# PTM280xx register map
File version: 0.4
Registers are 32-bit, read-write, reset 0x0 unless marked. A register's access mark holds for its fields unless they carry their own. Offsets are from the block's base; [hi:lo] are bit positions; {n}, {i} and the like mark numbered series.

## UART0 — Universal Asynchronous Receiver Transmitter
Base 0x40004400
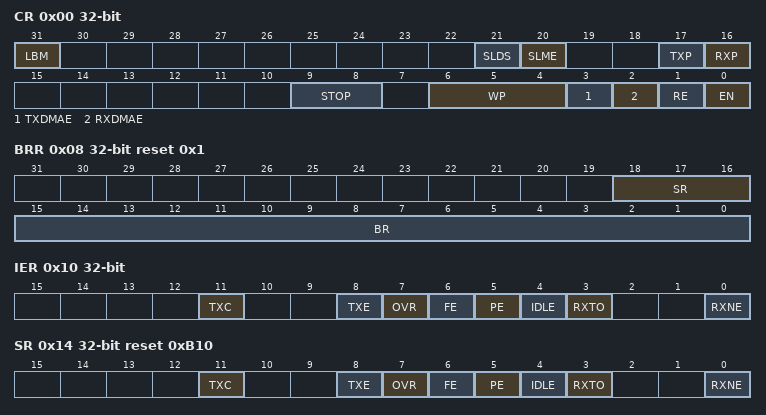
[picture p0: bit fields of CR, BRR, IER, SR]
0x00 CR — Control Register
  [31] LBM — loopback mode
  [21] SLDS — Single-line direction setting
  [20] SLME — Single-line mode enable
  [17] TXP — Transmitter polarity control
  [16] RXP — Receiver polarity control
  [9:8] STOP — Stop bit length
  [6:4] WP — Word length and parity config
  [3] TXDMAE — Tx DMA request enable
  [2] RXDMAE — Rx DMA request enable
  [1] RE — Receive enable
  [0] EN — UART enable
0x08 BRR reset 0x1 — Baud Rate Register
  [18:16] SR — Sample rate
  [15:0] BR — Baud rate control
0x10 IER — Interrupt Enable Register
  [11] TXC — Transmit complete interrupt enable
  [8] TXE — Transmit FIFO empty interrupt enable
  [7] OVR — Receive/Receive-FIFO overflow interrupt enable
  [6] FE — frame error interrupt enable
  [5] PE — parity error interrupt enable
  [4] IDLE — Idle timeout interrupt enable
  [3] RXTO — Receive/Receive-FIFO-clear timeout interrupt enable
  [0] RXNE — Receive/Receive-FIFO not empty interrupt enable
0x14 SR reset 0xB10 — Status Register
  [11] TXC ro — Transmit complete flag
  [8] TXE ro — Transmit/Transmit-FIFO empty flag
  [7] OVR — Receive/Receive-FIFO overflow flag
  [6] FE — Frame error flag
  [5] PE — Parity error flag
  [4] IDLE — Idle overtime interrupt enable
  [3] RXTO ro — Receive/Receive-FIFO-clear timeout flag
  [0] RXNE — Receive/Receive-FIFO not empty flag
0x18 DR — Data Register
  [8:0] DR — UART data
0x20 FITR — Frame Interval Time Configuration Register
  [7:0] FIT — Frame interval time
0x20 FITR — Frame Interval Time Configuration Register
  [7:0] FIT — Frame interval time
0x24 TCR — Timeout Control Register
  [7:0] TO — timeout

## OPA0
Base 0x40015C00
Same registers: OPA1 0x40015D00
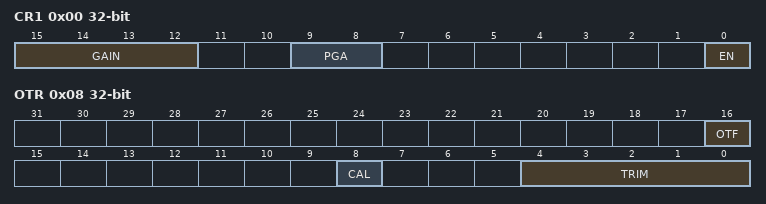
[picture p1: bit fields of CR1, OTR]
0x00 CR1 — Control Register 1
  [15:12] GAIN — PGA programmable amplifier gain value
  [9:8] PGA — PGA mode
  [0] EN — OPA enable
0x08 OTR access per field — Offset Trimming Register
  [16] OTF ro — Offset trimming value source flag
  [8] CAL ro — OPA calibration output
  [4:0] TRIM rw — Offset trimming value

## CMP0
Base 0x40000800
Same registers: CMP1 0x40000C00
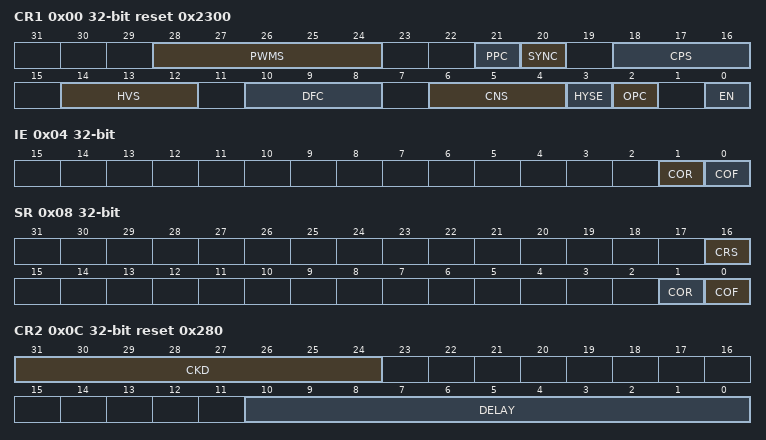
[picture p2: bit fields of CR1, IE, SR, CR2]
0x00 CR1 reset 0x2300 — Control Register 1
  [28:24] PWMS — Comparator output PWM selection
  [21] PPC — Comparator output PWM polarity control
  [20] SYNC — Comparator output synchronization control
  [18:16] CPS — Comparator positive intput selection
  [14:12] HVS — Comparator hysteresis voltage selection
  [10:8] DFC — Digital filter configuration
  [6:4] CNS — Comparator negative intput selection
  [3] HYSE — Comparator hysteresis enable
  [2] OPC — Comparator output polarity control
  [0] EN — Comparator enable
0x04 IE — Interrupt Enable Register
  [1] COR — Comparator output rising edge interrupt enable
  [0] COF — Comparator output falling edge interrupt enable
0x08 SR access per field — Status Register
  [16] CRS ro — Comparator result
  [1] COR rw — Comparator output rising edge flag
  [0] COF rw — Comparator output falling edge flag
0x0C CR2 access per field reset 0x280 — Control Register 2
  [31:24] CKD ro — Sampling clock division
  [10:0] DELAY rw — Comparator Initialization delay time

## LDAC
Base 0x40014000
0x00 CR — Control Register
  [0] EN — LDAC enable
0x04 DR — Data Register
  [4:0] DATA — LDAC data

## ALU — Arithmetic Logic Unit
Base 0x40030000
0x00 CR — Control Register
  [24] SIGN — Operand sign bit enable
0x04 IER — Interrupt Enable Register
  [1] ERRIE — Operation error interrupt enable
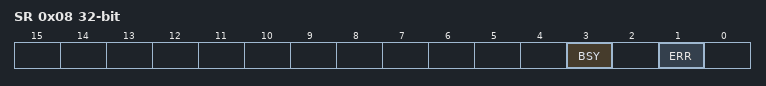
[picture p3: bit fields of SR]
0x08 SR — Status Register
  [3] BSY — Operation busy flag
  [1] ERR — Operation error flag
0x0C OPDXR — Operand X Register
  [31:0] OPDX — Operand X
0x10 OPDYR — Operand Y Register
  [31:0] OPDY — Operand Y
0x14 OPDZR — Operand Z Register
  [31:0] OPDZ — Operand Z
0x1C DHR ro — Data High 32-bit Register
  [31:0] DATAH — Data low 32-bit
0x20 DLR ro — Data Low 32-bit Register
  [31:0] DATAL — Data low 32-bit
0x24 DRR ro — Division Remainder Register
  [31:0] ROD — Remainder of division

## IFMC — On-chip flash memory controller
Base 0x40000000
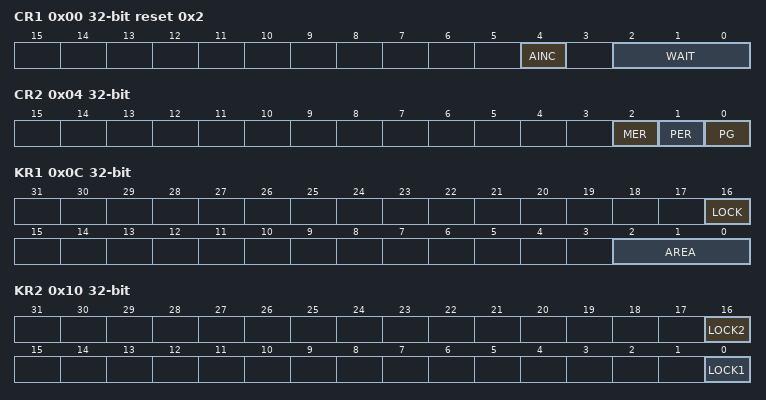
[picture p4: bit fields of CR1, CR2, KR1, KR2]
0x00 CR1 reset 0x2 — Control Register 1
  [4] AINC — Address auto increment control
  [2:0] WAIT — instruction fetch wait cycle
0x04 CR2 wo — Control Register 2
  [2] MER — Mass erase
  [1] PER — Pageerase
  [0] PG — Programming
0x08 PSCR access per field reset 0x40 — Prescaler Register
  [7:0] PSC rw — Prescaler value
  [7:0] PSC ro — Prescaler value
0x0C KR1 ro — Key Register 1
  [16] LOCK — Register lock status
  [2:0] AREA — IFMC operation area
0x10 KR2 ro — Key Register 2
  [16] LOCK2 — Register lock status 2
  [0] LOCK1 — Register lock status 1
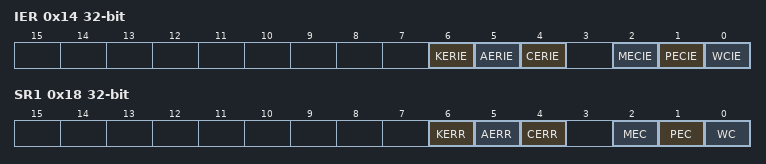
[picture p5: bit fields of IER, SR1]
0x14 IER — Interrupt Enable Register
  [6] KERIE — Key error interrupt enable
  [5] AERIE — Address error interrupt enable
  [4] CERIE — Operation command error interrupt enable
  [2] MECIE — Mass erase operation complete interrupt enable
  [1] PECIE — Page erase operation complete interrupt enable
  [0] WCIE — Write operation complete interrupt enable
0x18 SR1 — Status Register 1
  [6] KERR — Key error
  [5] AERR — Address error
  [4] CERR — Operation command error
  [2] MEC — Mass erase operation complete
  [1] PEC — Page erase operation complete
  [0] WC — Write operation complete
0x20 AR reset 0xFFFFFFFF — Address Register
  [31:0] AR — IFMC words addr
0x24 DR1 — Data Register 1
  [31:0] DR — IFMC data
0x30 OPTCR reset 0xAA — Option Control Register
  [7:0] RDP — Read protect

## ES — Device Electronic Signature
Base 0x40020800
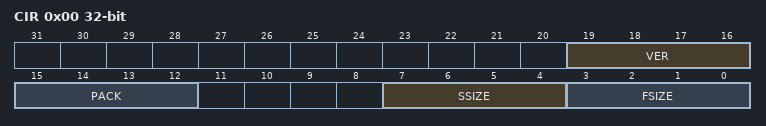
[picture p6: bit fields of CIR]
0x00 CIR ro — Chip Information Register
  [19:16] VER — Chip version information
  [15:12] PACK — Package
  [7:4] SSIZE — Size of sram memory
  [3:0] FSIZE — Size of flash memory
0x0C CIDR1 ro reset 0xFFFFFFFF — Chip ID Register 1
  [31:0] CID — Chip ID
0x10 CIDR2 ro — Chip ID Register 2
  [31:0] CID — Chip ID
0x14 CIDR3 ro — Chip ID Register 3
  [31:0] CID — Chip ID
{0x14+4i} UDIR{i} reset 0xFFFFFFFF (i=1..3) — User-Defined Information Register {i}
  [31:0] INFO — User-defined information

## SYSCFG — System Configuration
Base 0x40020C00
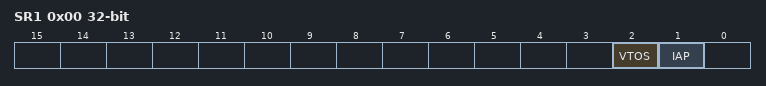
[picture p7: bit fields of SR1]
0x00 SR1 access per field — Status Register 1
  [2] VTOS rw — Interrupt vector table location selection flag
  [1] IAP ro — IAP enable flag
0x14 IAPAR — IAP Address Register
  [31:0] ADDR — IAP address
0x18 SVTOR — SRAM Interrupt Vector Table Address Register
  [31:0] ADDR — SRAM interrupt vector table address
